# GD32A503 register map
File version: 1.0
CPU: CM33 r0p4, little endian, MPU, FPU, 4 interrupt priority bits
Registers are 32-bit, read-write, reset 0x0 unless marked. A register's access mark holds for its fields unless they carry their own. Offsets are from the block's base; [hi:lo] are bit positions; lines under a group give offsets from that group; {n}, {i} and the like mark numbered series.

## ADC0 — Analog to digital converter
Base 0x40012400
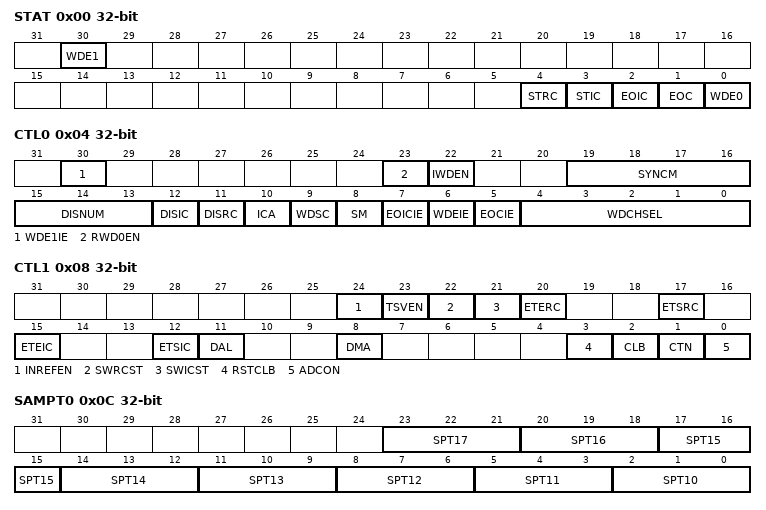
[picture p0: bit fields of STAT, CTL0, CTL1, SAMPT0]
0x00 STAT — status register
  [30] WDE1 — Analog watchdog 1 event flag
  [4] STRC — Start flag of regular channel group
  [3] STIC — Start flag of inserted channel group
  [2] EOIC — End of inserted group conversion flag
  [1] EOC — End of group conversion flag
  [0] WDE0 — Analog watchdog event 0 flag
0x04 CTL0 — control register 0
  [30] WDE1IE — Interrupt enable for WDE1
  [23] RWD0EN — Regular channel analog watchdog enable
  [22] IWDEN — Inserted channel analog watchdog enable
  [19:16] SYNCM — Sync mode selection
  [15:13] DISNUM — Number of conversions in discontinuous mode
  [12] DISIC — Discontinuous mode on inserted channels
  [11] DISRC — Discontinuous mode on regular channels
  [10] ICA — Inserted channel group convert automatically
  [9] WDSC — When in scan mode, analog watchdog is effective on a single channel
  [8] SM — Scan mode
  [7] EOICIE — Interrupt enable for EOIC
  [6] WDEIE — Analog watchdog WDE
  [5] EOCIE — Interrupt enable for EOC
  [4:0] WDCHSEL — Analog watchdog channel select
0x08 CTL1 — control register 1
  [24] INREFEN — Channel 17 (internal reference voltage) enable of ADC0
  [23] TSVEN — Channel 16 (temperature sensor) enable of ADC0
  [22] SWRCST — Start on regular channel
  [21] SWICST — Start on inserted channel
  [20] ETERC — External trigger select for regular channel
  [17] ETSRC — External trigger select for regular channel
  [15] ETEIC — External trigger enable for inserted channel
  [12] ETSIC — External trigger select for inserted channel
  [11] DAL — Data alignment
  [8] DMA — DMA request enable
  [3] RSTCLB — Reset calibration
  [2] CLB — ADC calibration
  [1] CTN — Continuous mode
  [0] ADCON
0x0C SAMPT0 — Sample time register 0
  [3n-28:3n-30] SPT{n} (n=10..17) — Channel {n} sample time selection
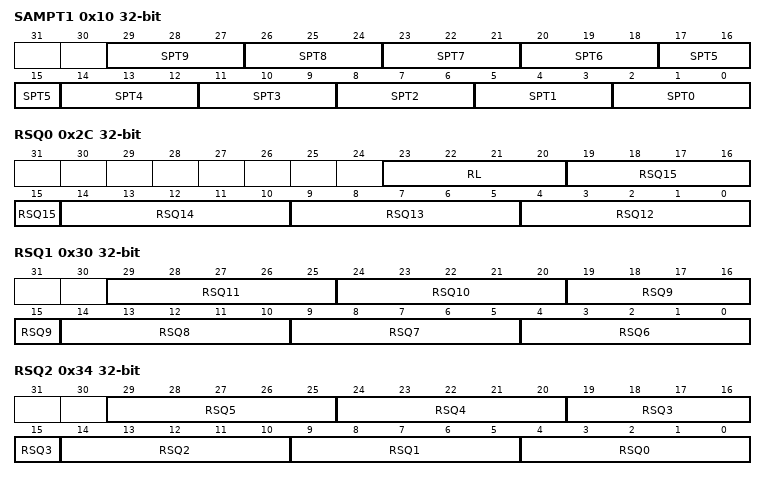
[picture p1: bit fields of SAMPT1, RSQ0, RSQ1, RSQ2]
0x10 SAMPT1 — Sample time register 1
  [3n+2:3n] SPT{n} (n=0..9) — Channel {n} sample time selection
{0x14+4i} IOFF{i} (i=0..3) — Inserted channel data offset register {i}
  [11:0] IOFF — Data offset for inserted channel {i}
0x24 WDHT0 reset 0xFFF — watchdog higher threshold register
  [11:0] WDHT0 — Analog watchdog higher threshold
0x28 WDLT0 — watchdog lower threshold register
  [11:0] WDLT0 — Analog watchdog lower threshold
0x2C RSQ0 — regular sequence register 0
  [23:20] RL — Regular channel group length
  [5n-56:5n-60] RSQ{n} (n=12..15) — {n}th conversion in regular sequence
0x30 RSQ1 — regular sequence register 1
  [29:25] RSQ11 — 11th conversion in regular sequence
  [24:20] RSQ10 — 10th conversion in regular sequence
  [19:15] RSQ9 — 9th conversion in regular sequence
  [14:10] RSQ8 — 9th conversion in regular sequence
  [9:5] RSQ7 — 8th conversion in regular sequence
  [4:0] RSQ6 — 7th conversion in regular sequence
0x34 RSQ2 — regular sequence register 2
  [29:25] RSQ5 — 6th conversion in regular sequence
  [24:20] RSQ4 — 5th conversion in regular sequence
  [19:15] RSQ3 — 4th conversion in regular sequence
  [14:10] RSQ2 — 3rd conversion in regular sequence
  [9:5] RSQ1 — 2nd conversion in regular sequence
  [4:0] RSQ0 — 1st conversion in regular sequence
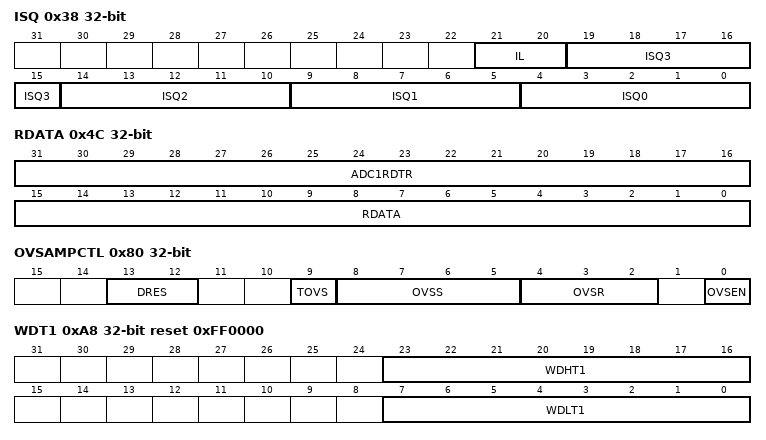
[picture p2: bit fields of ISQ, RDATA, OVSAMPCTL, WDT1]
0x38 ISQ — Inserted sequence register
  [21:20] IL — Inserted channel group length
  [19:15] ISQ3 — 4th conversion in inserted sequence
  [14:10] ISQ2 — 3rd conversion in inserted sequence
  [9:5] ISQ1 — 2nd conversion in inserted sequence
  [4:0] ISQ0 — 1st conversion in inserted sequence
{0x3C+4i} IDATA{i} ro (i=0..3) — Inserted data register {i}
  [15:0] IDATAn — Inserted number {i} conversion data
0x4C RDATA ro — regular data register
  [31:16] ADC1RDTR — ADC1 regular channel data
  [15:0] RDATA — Regular channel data
0x80 OVSAMPCTL ro — Oversample control register
  [13:12] DRES — ADC resolution
  [9] TOVS — Triggered Oversampling
  [8:5] OVSS — Oversampling shift
  [4:2] OVSR — Oversampling ratio
  [0] OVSEN — Oversampling Enable
0xA0 WD1SR — Watchdog 1 Channel Selection Register
  [17:0] AWD1CS — Analog watchdog 1 channel selection
0xA8 WDT1 reset 0xFF0000 — Watchdog threshold register 1
  [23:16] WDHT1 — Analog watchdog 1 channel selection
  [7:0] WDLT1 — Analog watchdog 1 low threshold

## ADC1 — Analog to digital converter
Base 0x40012800
Registers as ADC0; these are added or differ:
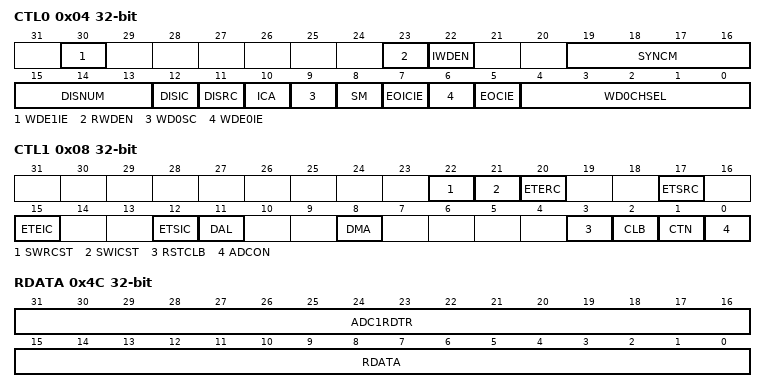
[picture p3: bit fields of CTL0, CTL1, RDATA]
0x04 CTL0 — control register 0
  [30] WDE1IE — Interrupt enable for WDE1
  [23] RWDEN — Regular channel analog watchdog enable
  [22] IWDEN — Inserted channel analog watchdog enable
  [19:16] SYNCM — Sync mode selection
  [15:13] DISNUM — Number of conversions in discontinuous mode
  [12] DISIC — Discontinuous mode on inserted channels
  [11] DISRC — Discontinuous mode on regular channels
  [10] ICA — Inserted channel group convert automatically
  [9] WD0SC — When in scan mode, analog watchdog is effective on a single channel
  [8] SM — Scan mode
  [7] EOICIE — Interrupt enable for EOIC
  [6] WDE0IE — Analog watchdog WDE0
  [5] EOCIE — Interrupt enable for EOC
  [4:0] WD0CHSEL — Analog watchdog 0 channel select
0x08 CTL1 — control register 1
  [22] SWRCST — Start on regular channel
  [21] SWICST — Start on inserted channel
  [20] ETERC — External trigger select for regular channel
  [17] ETSRC — External trigger select for regular channel
  [15] ETEIC — External trigger enable for inserted channel
  [12] ETSIC — External trigger select for inserted channel
  [11] DAL — Data alignment
  [8] DMA — DMA request enable
  [3] RSTCLB — Reset calibration
  [2] CLB — ADC calibration
  [1] CTN — Continuous mode
  [0] ADCON
0x4C RDATA ro — regular data register
  [31:16] ADC1RDTR — ADC1 regular channel data
  [15:0] RDATA — Regular channel data
